# R7KA8P1AD register map
Vendor: Renesas Electronics Corporation; Series: RA8; File version: 1.10.02
CPU: CM85 r0p2, little endian, MPU, FPU, VTOR, 4 interrupt priority bits, 96 interrupts
Registers are 32-bit, read-write, reset 0x0 unless marked. A register's access mark holds for its fields unless they carry their own. Offsets are from the block's base; [hi:lo] are bit positions; {n}, {i} and the like mark numbered series.

## CPU_CTRL
Base 0x4000F000
{0x30+4i} CPU{i}LCKUPCR (i=0..1) 8-bit — CPU{i} Lockup Control Register
  [0] OAD — Operation after detection of CPUn lockup
    0=Non-maskable interrupt; 1=System reset
{0x40+4i} CPU{i}INITVTOR (i=0..1) reset 0x2000000 — CPU Initial Vector Base Address Register
  [31:0] CPUINITVTOR — CPUn Initial Vector Base Address
{0x50+4i} CPU{i}WAITCR (i=0..1) 8-bit — CPU{i} CPUWAIT Control Register
  [0] CPUWAIT — Writing 1 to stall the CPUn when it is out of reset.
    0=CPUn starts instruction execution out of reset; 1=CPUn is forced into a quiescent state out of reset
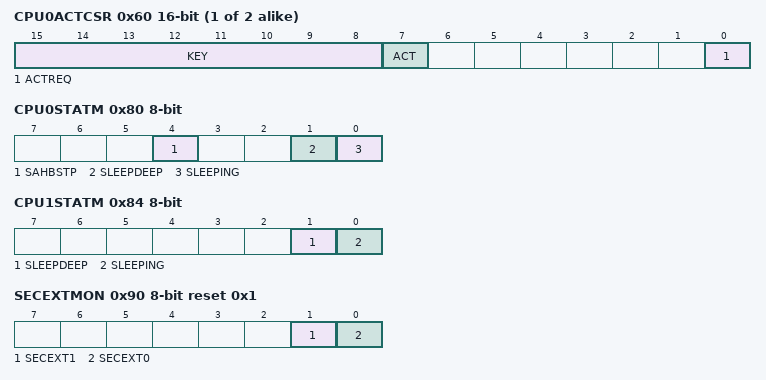
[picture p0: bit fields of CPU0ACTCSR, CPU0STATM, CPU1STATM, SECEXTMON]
{0x60+4i} CPU{i}ACTCSR (i=0..1) 16-bit (reset mask 0xFF7F) — CPU{i} Activation Control and Status Register
  [15:8] KEY — Key Code
  [7] ACT ro — CPUn activation status
    0=CPUn is in inactive state (power gating/reset state); 1=CPUn is in active state (out of reset)
  [0] ACTREQ — CPUn activation request
    0=No effect; 1=Request CPUn activation if ACT bit is 0
0x70 CPU0LMECR 8-bit — CPU0 Local Memory Error Control Register
  [0] SYRSTEN — System Reset Request Enable
    0=Disables system reset request when multiple bits error occurs in data cache or TCM; 1=Enables system reset request when multiple bits error occurs in data cache or TCM
0x78 CPUIDR 8-bit — CPU Identification Register
  [0] CPUID ro — CPU Identification
    0=CPU0; 1=CPU1
0x80 CPU0STATM 8-bit — CPU0 Status Monitor Register
  [4] SAHBSTP ro
    0=CPU0 S-AHB is active; 1=CPU0 S-AHB is stopped
  [1] SLEEPDEEP ro — CPU0 SLEEPDEEP state
  [0] SLEEPING ro — CPU0 Sleeping State
    0=CPU0 is running; 1=CPU0 is at Sleep mode
0x84 CPU1STATM 8-bit — CPU1 Status Monitor Register
  [1] SLEEPDEEP ro — CPU1 SLEEPDEEP state
  [0] SLEEPING ro — CPU1 Sleeping State
    0=CPU1 is running; 1=CPU1 is at Sleep mode
0x90 SECEXTMON 8-bit reset 0x1 (reset mask 0xFD) — CPU SECEXT Monitor Register
  [1] SECEXT1 ro — CPU1 Security Extension
    0=CPU1 does not include Security Extension; 1=CPU1 includes Security Extension
  [0] SECEXT0 ro — CPU0 Security Extension
    0=CPU0 does not include Security Extension; 1=CPU0 includes Security Extension
0x94 NSCPUCR reset 0x1 — Non-secure CPU Control Register
  [0] RSTREQEN — System Reset Request Enable
    0=System reset request caused by non-secure CPU without SECEXT is not allowed; 1=System reset request caused by non-secure CPU without SECEXT is allowed
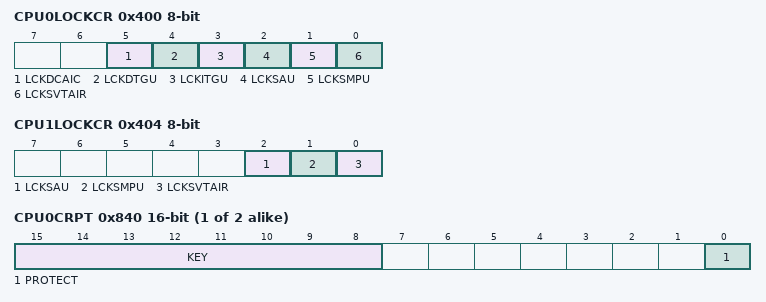
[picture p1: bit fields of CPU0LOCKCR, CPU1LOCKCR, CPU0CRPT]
0x400 CPU0LOCKCR 8-bit — CPU0 Function Lock Control Register
  [5] LCKDCAIC
  [4] LCKDTGU — DTGUCTRL, DTGU_LUTn
  [3] LCKITGU — ITGUCTRL, ITGU_LUTn
  [2] LCKSAU — This signal disables writes to registers that are associated with the SAU region from software or from a debug agent connected to the processor.
  [1] LCKSMPU — Disables writes to registers that are associated with the Secure MPU region from software or from a debug agent connected to the processor.
  [0] LCKSVTAIR — Disables writes to the following secure registers from software or from a debug agent that is connected to the processor.
0x404 CPU1LOCKCR 8-bit — CPU1 Function Lock Control Register
  [2] LCKSAU — This signal disables writes to registers that are associated with the SAU region from software or from a debug agent connected to the processor.
  [1] LCKSMPU — Disables writes to registers that are associated with the Secure MPU region from software or from a debug agent connected to the processor.
  [0] LCKSVTAIR — Disables writes to the following secure registers from software or from a debug agent that is connected to the processor.
{0x840+4i} CPU{i}CRPT (i=0..1) 16-bit — CPU{i} Control Register Protection Register
  [15:8] KEY wo — The KEY[7:0] bits enable or disable writing to the PROTECT bit.
  [0] PROTECT — Protection of register
    0=Writing to CPUnLCKUPCR register is available; 1=Writing to CPUnLCKUPCR register is not available. Read access is available.

## CPU_CTRL_NS — CPU(CTRL)
Base 0x5000F000
Registers as CPU_CTRL, without CPU*WAITCR, CPU*ACTCSR, CPU0LMECR, CPUIDR, CPU0STATM, CPU1STATM, SECEXTMON, NSCPUCR, CPU0LOCKCR, CPU1LOCKCR; these are added or differ:
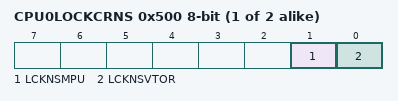
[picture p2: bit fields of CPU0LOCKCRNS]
{0x500+4i} CPU{i}LOCKCRNS (i=0..1) 8-bit — CPU{i} Non-secure Function Lock Control Register
  [1] LCKNSMPU — Disables writes to registers that are associated with the Non-secure MPU region from software or from a debug agent connected to the processor.
  [0] LCKNSVTOR
